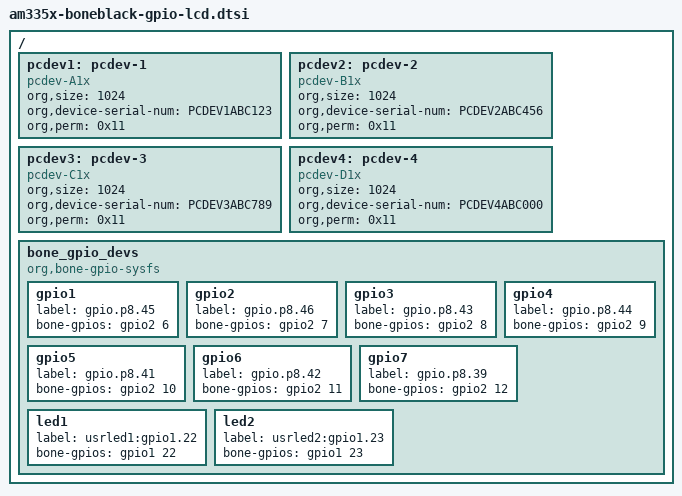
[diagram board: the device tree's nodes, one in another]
/{
	pcdev1: pcdev-1 {
		compatible = "pcdev-A1x";
    		org,size = <1024>;
    		org,device-serial-num = "PCDEV1ABC123";
    		org,perm = <0x11>;
  	};

  	pcdev2: pcdev-2 {
    		compatible = "pcdev-B1x";
    		org,size = <1024>;
    		org,device-serial-num = "PCDEV2ABC456";
    		org,perm = <0x11>;
  	};

  	pcdev3: pcdev-3 {
    		compatible = "pcdev-C1x";
    		org,size = <1024>;
    		org,device-serial-num= "PCDEV3ABC789";
		org,perm = <0x11>;
  		};

  	pcdev4: pcdev-4 {
    		compatible = "pcdev-D1x";
    		org,size = <1024>;
    		org,device-serial-num= "PCDEV4ABC000";
    		org,perm = <0x11>;
  	};
  	
	bone_gpio_devs {
		compatible = "org,bone-gpio-sysfs";
		
		gpio1{
			label = "gpio.p8.45";
			bone-gpios = <&gpio2 6 GPIO_ACTIVE_HIGH>;
		
		};
		
		gpio2{
			label = "gpio.p8.46";
			bone-gpios = <&gpio2 7 GPIO_ACTIVE_HIGH>;
	
		};
	
		gpio3{
			label = "gpio.p8.43";
			bone-gpios = <&gpio2 8 GPIO_ACTIVE_HIGH>;
	
		};	
	
		gpio4{
			label = "gpio.p8.44";
			bone-gpios = <&gpio2 9 GPIO_ACTIVE_HIGH>;
		
		};
		
		gpio5{
			label = "gpio.p8.41";
			bone-gpios = <&gpio2 10 GPIO_ACTIVE_HIGH>;
		
		};
		
		gpio6{
			label = "gpio.p8.42";
			bone-gpios = <&gpio2 11 GPIO_ACTIVE_HIGH>;
		
		};
				
		gpio7{
			label = "gpio.p8.39";
			bone-gpios = <&gpio2 12 GPIO_ACTIVE_HIGH>;
		
		};
				
		led1{
			label = "usrled1:gpio1.22";
			bone-gpios = <&gpio1 22 GPIO_ACTIVE_HIGH>;
		};
		
		led2{
			label = "usrled2:gpio1.23";
			bone-gpios = <&gpio1 23 GPIO_ACTIVE_HIGH>;
		};	
		
	
	};//bone_gpio_deb
};//root node	









